AUTOSAR XML (schema 00044)
package /ComponentTypes
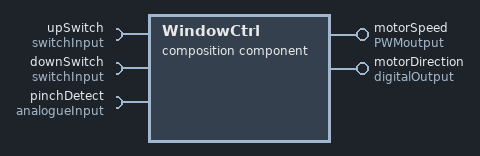
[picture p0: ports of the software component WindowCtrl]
  composition sw component type WindowCtrl
    require port upSwitch: nonqueued-receiver-com-spec=data-element=switchState, required-interface=switchInput
    require port downSwitch: nonqueued-receiver-com-spec=data-element=switchState, required-interface=switchInput
    provide port motorSpeed: nonqueued-sender-com-spec=dutyCycle, provided-interface=PWMoutput
    provide port motorDirection: nonqueued-sender-com-spec=outputStatus, provided-interface=digitalOutput
    require port pinchDetect: nonqueued-receiver-com-spec=data-element=ADCinput, required-interface=analogueInput
    component switchDetector: type=switchDetector
    component motorControl: type=motorControl
    component pinchDetector: type=pinchDetector
    delegate switchDetector.UpSwitchInput <-> outer port upSwitch
    delegate switchDetector.DownSwitchInput <-> outer port downSwitch
    delegate pinchDetector.pinchADC <-> outer port pinchDetect
    delegate motorControl.motorPWM <-> outer port motorSpeed
    delegate switchDetector.motorDir <-> outer port motorDirection
    connect pinchDetector.motorStop -> motorControl.EStop
    connect switchDetector.motorStatus -> motorControl.motorOnOff
